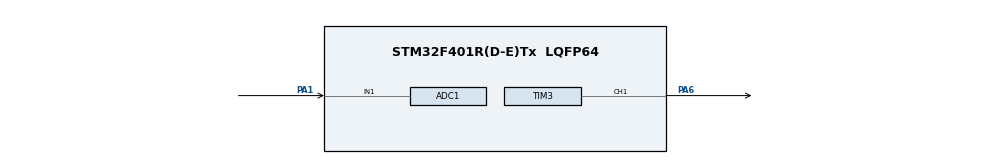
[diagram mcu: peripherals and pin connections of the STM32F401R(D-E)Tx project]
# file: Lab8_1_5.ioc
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ADC1.Channel-1\#ChannelRegularConversion=ADC_CHANNEL_1
ADC1.ContinuousConvMode=ENABLE
ADC1.EOCSelection=ADC_EOC_SEQ_CONV
ADC1.NbrOfConversionFlag=1
ADC1.Rank-1\#ChannelRegularConversion=1
ADC1.Resolution=ADC_RESOLUTION_8B
ADC1.SamplingTime-1\#ChannelRegularConversion=ADC_SAMPLETIME_3CYCLES
ADC1.master=1
Mcu.Family=STM32F4
Mcu.Name=STM32F401R(D-E)Tx
Mcu.Package=LQFP64
NVIC.PriorityGroup=NVIC_PRIORITYGROUP_4
PA1.Signal=ADCx_IN1
PA6.Signal=S_TIM3_CH1
ProjectManager.HeapSize=0x200
ProjectManager.StackSize=0x400
ProjectManager.TargetToolchain=STM32CubeIDE
RCC.48MHZClocksFreq_Value=84000000
RCC.AHBFreq_Value=84000000
RCC.APB1CLKDivider=RCC_HCLK_DIV2
RCC.APB1Freq_Value=42000000
RCC.APB1TimFreq_Value=84000000
RCC.APB2Freq_Value=84000000
RCC.APB2TimFreq_Value=84000000
RCC.CortexFreq_Value=84000000
RCC.HCLKFreq_Value=84000000
RCC.HSE_VALUE=25000000
RCC.HSI_VALUE=16000000
RCC.LSE_VALUE=32768
RCC.PLLN=336
RCC.PLLP=RCC_PLLP_DIV4
RCC.SYSCLKFreq_VALUE=84000000
RCC.SYSCLKSource=RCC_SYSCLKSOURCE_PLLCLK
RCC.VCOOutputFreq_Value=336000000
SH.ADCx_IN1.0=ADC1_IN1,IN1
SH.S_TIM3_CH1.0=TIM3_CH1,Output Compare1 CH1
TIM3.Channel-Output\ Compare1\ CH1=TIM_CHANNEL_1
TIM3.OCMode_1=TIM_OCMODE_TOGGLE
VP_TIM3_VS_ClockSourceINT.Mode=Internal
board=custom

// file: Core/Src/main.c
/* USER CODE BEGIN Header */
/**
  ******************************************************************************
  * @file           : main.c
  * @brief          : Main program body
  ******************************************************************************
  * @attention
  *
  * Copyright (c) 2026 STMicroelectronics.
  * All rights reserved.
  *
  * This software is licensed under terms that can be found in the LICENSE file
  * in the root directory of this software component.
  * If no LICENSE file comes with this software, it is provided AS-IS.
  *
  ******************************************************************************
  */
/* USER CODE END Header */
#include "main.h"

/* USER CODE BEGIN PD */
#define ADC_MAX_VALUE         255U   // Resolution is 8 bit
#define ADC_DATA_MASK        0xFFU   // Extract only 8 rightmost bits
#define TIM3_CLOCK_HZ     1000000U   // f = 1 MHz
#define OUTPUT_FREQ_MIN_HZ      800U // Range = 800 - 4500 Hz
#define OUTPUT_FREQ_MAX_HZ     4500U

/* USER CODE END PD */

void SystemClock_Config(void);
static void MX_GPIO_Init(void);
static void MX_ADC1_Init(void);
static void MX_TIM3_Init(void);

/* USER CODE BEGIN 0 */
static uint16_t ADC_to_STEP(uint16_t adc_value)
{
  uint32_t frequency_range = OUTPUT_FREQ_MAX_HZ - OUTPUT_FREQ_MIN_HZ;

  // adc_value : ADC_MAX_VALUE = frequency_offset : frequency_range
  uint32_t frequency_offset = ((uint32_t)adc_value * frequency_range) / ADC_MAX_VALUE;

  uint32_t output_frequency = OUTPUT_FREQ_MIN_HZ + frequency_offset; // We start from 800Hz

  uint32_t timer_ticks_per_period = TIM3_CLOCK_HZ / output_frequency;
  uint32_t timer_ticks_per_toggle = timer_ticks_per_period / 2U;

  return (uint16_t)timer_ticks_per_toggle;
}

/* USER CODE END 0 */

int main(void)
{

  /* MCU Configuration--------------------------------------------------------*/

  /* Reset of all peripherals, Initializes the Flash interface and the Systick. */
  LL_APB2_GRP1_EnableClock(LL_APB2_GRP1_PERIPH_SYSCFG);
  LL_APB1_GRP1_EnableClock(LL_APB1_GRP1_PERIPH_PWR);

  /* System interrupt init*/
  NVIC_SetPriorityGrouping(NVIC_PRIORITYGROUP_4);

  /* SysTick_IRQn interrupt configuration */
  NVIC_SetPriority(SysTick_IRQn, NVIC_EncodePriority(NVIC_GetPriorityGrouping(),15, 0));

  /* Configure the system clock */
  SystemClock_Config();

  /* Initialize all configured peripherals */
  MX_GPIO_Init();
  MX_ADC1_Init();
  MX_TIM3_Init();
  /* USER CODE BEGIN 2 */
  SysTick_Config(SystemCoreClock / 1000);

  // Initialize OC with min step
  uint16_t tim3_step = ADC_to_STEP(0U);
  LL_TIM_OC_SetCompareCH1(TIM3, LL_TIM_GetCounter(TIM3) + tim3_step);
  LL_TIM_ClearFlag_CC1(TIM3);

  // Initialize ADC
  LL_ADC_WriteReg(ADC1, SR, 0);
  LL_ADC_WriteReg(ADC1, CR2, LL_ADC_ReadReg(ADC1, CR2) | ADC_CR2_ADON);

  for (volatile uint32_t i = 0; i < 1000; i++) {
  }

  LL_ADC_WriteReg(ADC1, CR2, LL_ADC_ReadReg(ADC1, CR2) | ADC_CR2_SWSTART);

  // Start Counter
  LL_TIM_EnableCounter(TIM3);

  /* USER CODE END 2 */

  /* Infinite loop */
  while (1)
  {

    /* USER CODE BEGIN 3 */

    // Check if EOC is reached, compute new step with acquired value
    if (LL_ADC_ReadReg(ADC1, SR) & ADC_SR_EOC) {
      uint16_t adc_value = (uint16_t)(LL_ADC_ReadReg(ADC1, DR) & ADC_DATA_MASK);
      LL_ADC_WriteReg(ADC1, SR, 0);

      tim3_step = ADC_to_STEP(adc_value);
    }

    // Clear CC flag if set (toggling is handled by the timer)
    if (LL_TIM_IsActiveFlag_CC1(TIM3)) {
      LL_TIM_ClearFlag_CC1(TIM3);

      // Update with new step
      LL_TIM_OC_SetCompareCH1(TIM3,
          LL_TIM_OC_GetCompareCH1(TIM3) + tim3_step);
    }
  }
  /* USER CODE END 3 */
}

void SystemClock_Config(void)
{
  LL_FLASH_SetLatency(LL_FLASH_LATENCY_2);
  while(LL_FLASH_GetLatency()!= LL_FLASH_LATENCY_2)
  {
  }
  LL_PWR_SetRegulVoltageScaling(LL_PWR_REGU_VOLTAGE_SCALE2);
  LL_RCC_HSI_SetCalibTrimming(16);
  LL_RCC_HSI_Enable();

   /* Wait till HSI is ready */
  while(LL_RCC_HSI_IsReady() != 1)
  {

  }
  LL_RCC_PLL_ConfigDomain_SYS(LL_RCC_PLLSOURCE_HSI, LL_RCC_PLLM_DIV_16, 336, LL_RCC_PLLP_DIV_4);
  LL_RCC_PLL_Enable();

   /* Wait till PLL is ready */
  while(LL_RCC_PLL_IsReady() != 1)
  {

  }
  while (LL_PWR_IsActiveFlag_VOS() == 0)
  {
  }
  LL_RCC_SetAHBPrescaler(LL_RCC_SYSCLK_DIV_1);
  LL_RCC_SetAPB1Prescaler(LL_RCC_APB1_DIV_2);
  LL_RCC_SetAPB2Prescaler(LL_RCC_APB2_DIV_1);
  LL_RCC_SetSysClkSource(LL_RCC_SYS_CLKSOURCE_PLL);

   /* Wait till System clock is ready */
  while(LL_RCC_GetSysClkSource() != LL_RCC_SYS_CLKSOURCE_STATUS_PLL)
  {

  }
  LL_Init1msTick(84000000);
  LL_SetSystemCoreClock(84000000);
  LL_RCC_SetTIMPrescaler(LL_RCC_TIM_PRESCALER_TWICE);
}

static void MX_ADC1_Init(void)
{

  LL_ADC_InitTypeDef ADC_InitStruct = {0};
  LL_ADC_REG_InitTypeDef ADC_REG_InitStruct = {0};
  LL_ADC_CommonInitTypeDef ADC_CommonInitStruct = {0};

  LL_GPIO_InitTypeDef GPIO_InitStruct = {0};

  /* Peripheral clock enable */
  LL_APB2_GRP1_EnableClock(LL_APB2_GRP1_PERIPH_ADC1);

  LL_AHB1_GRP1_EnableClock(LL_AHB1_GRP1_PERIPH_GPIOA);
  /**ADC1 GPIO Configuration
  PA1   ------> ADC1_IN1
  */
  GPIO_InitStruct.Pin = LL_GPIO_PIN_1;
  GPIO_InitStruct.Mode = LL_GPIO_MODE_ANALOG;
  GPIO_InitStruct.Pull = LL_GPIO_PULL_NO;
  LL_GPIO_Init(GPIOA, &GPIO_InitStruct);

  /** Common config
  */
  ADC_InitStruct.Resolution = LL_ADC_RESOLUTION_8B;
  ADC_InitStruct.DataAlignment = LL_ADC_DATA_ALIGN_RIGHT;
  ADC_InitStruct.SequencersScanMode = LL_ADC_SEQ_SCAN_DISABLE;
  LL_ADC_Init(ADC1, &ADC_InitStruct);
  ADC_REG_InitStruct.TriggerSource = LL_ADC_REG_TRIG_SOFTWARE;
  ADC_REG_InitStruct.SequencerLength = LL_ADC_REG_SEQ_SCAN_DISABLE;
  ADC_REG_InitStruct.SequencerDiscont = LL_ADC_REG_SEQ_DISCONT_DISABLE;
  ADC_REG_InitStruct.ContinuousMode = LL_ADC_REG_CONV_CONTINUOUS;
  ADC_REG_InitStruct.DMATransfer = LL_ADC_REG_DMA_TRANSFER_NONE;
  LL_ADC_REG_Init(ADC1, &ADC_REG_InitStruct);
  LL_ADC_REG_SetFlagEndOfConversion(ADC1, LL_ADC_REG_FLAG_EOC_SEQUENCE_CONV);
  ADC_CommonInitStruct.CommonClock = LL_ADC_CLOCK_SYNC_PCLK_DIV4;
  LL_ADC_CommonInit(__LL_ADC_COMMON_INSTANCE(ADC1), &ADC_CommonInitStruct);

  /** Configure Regular Channel
  */
  LL_ADC_REG_SetSequencerRanks(ADC1, LL_ADC_REG_RANK_1, LL_ADC_CHANNEL_1);
  LL_ADC_SetChannelSamplingTime(ADC1, LL_ADC_CHANNEL_1, LL_ADC_SAMPLINGTIME_3CYCLES);

}

static void MX_TIM3_Init(void)
{

  LL_TIM_InitTypeDef TIM_InitStruct = {0};
  LL_TIM_OC_InitTypeDef TIM_OC_InitStruct = {0};

  LL_GPIO_InitTypeDef GPIO_InitStruct = {0};

  /* Peripheral clock enable */
  LL_APB1_GRP1_EnableClock(LL_APB1_GRP1_PERIPH_TIM3);

  TIM_InitStruct.Prescaler = 83;
  TIM_InitStruct.CounterMode = LL_TIM_COUNTERMODE_UP;
  TIM_InitStruct.Autoreload = 65535;
  TIM_InitStruct.ClockDivision = LL_TIM_CLOCKDIVISION_DIV1;
  LL_TIM_Init(TIM3, &TIM_InitStruct);
  LL_TIM_DisableARRPreload(TIM3);
  LL_TIM_SetClockSource(TIM3, LL_TIM_CLOCKSOURCE_INTERNAL);
  TIM_OC_InitStruct.OCMode = LL_TIM_OCMODE_TOGGLE;
  TIM_OC_InitStruct.OCState = LL_TIM_OCSTATE_ENABLE;
  TIM_OC_InitStruct.OCNState = LL_TIM_OCSTATE_DISABLE;
  TIM_OC_InitStruct.CompareValue = 0;
  TIM_OC_InitStruct.OCPolarity = LL_TIM_OCPOLARITY_HIGH;
  LL_TIM_OC_Init(TIM3, LL_TIM_CHANNEL_CH1, &TIM_OC_InitStruct);
  LL_TIM_OC_DisableFast(TIM3, LL_TIM_CHANNEL_CH1);
  LL_TIM_SetTriggerOutput(TIM3, LL_TIM_TRGO_RESET);
  LL_TIM_DisableMasterSlaveMode(TIM3);
  LL_AHB1_GRP1_EnableClock(LL_AHB1_GRP1_PERIPH_GPIOA);
  /**TIM3 GPIO Configuration
  PA6   ------> TIM3_CH1
  */
  GPIO_InitStruct.Pin = LL_GPIO_PIN_6;
  GPIO_InitStruct.Mode = LL_GPIO_MODE_ALTERNATE;
  GPIO_InitStruct.Speed = LL_GPIO_SPEED_FREQ_LOW;
  GPIO_InitStruct.OutputType = LL_GPIO_OUTPUT_PUSHPULL;
  GPIO_InitStruct.Pull = LL_GPIO_PULL_NO;
  GPIO_InitStruct.Alternate = LL_GPIO_AF_2;
  LL_GPIO_Init(GPIOA, &GPIO_InitStruct);

}

static void MX_GPIO_Init(void)
{

  /* GPIO Ports Clock Enable */
  LL_AHB1_GRP1_EnableClock(LL_AHB1_GRP1_PERIPH_GPIOA);

}

void Error_Handler(void)
{
  __disable_irq();
  while (1)
  {
  }
}
